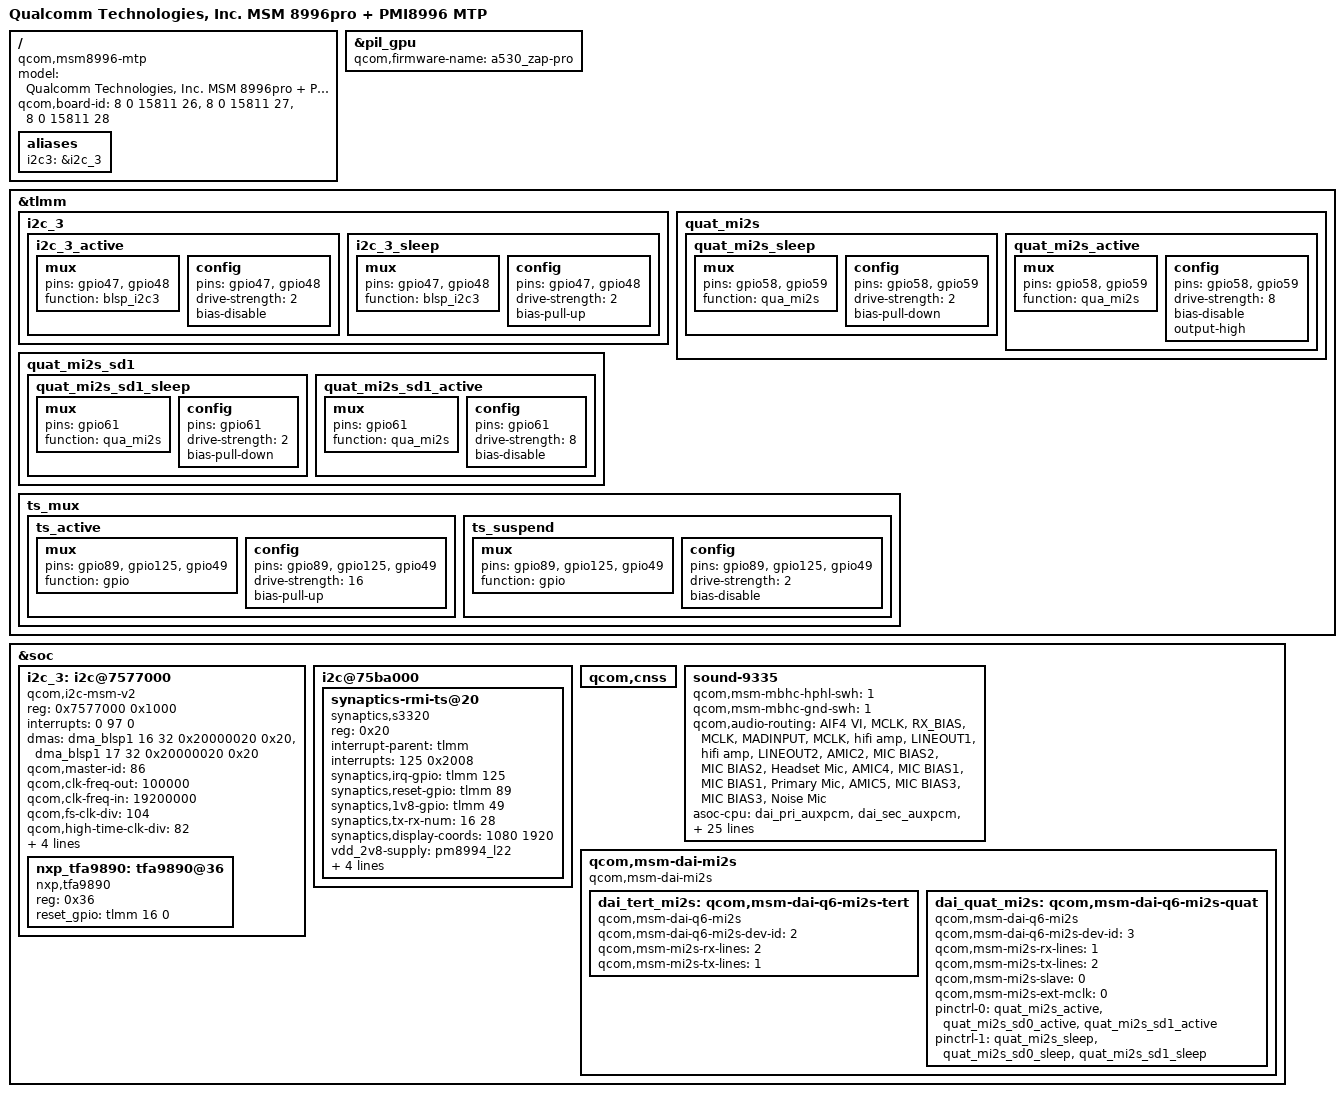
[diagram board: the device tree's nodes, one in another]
/*
 * Copyright (C) 2018, Comma.ai, Inc.
 *
 * This program is free software; you can redistribute it and/or modify
 * it under the terms of the GNU General Public License version 2 and
 * only version 2 as published by the Free Software Foundation.
 *
 * This program is distributed in the hope that it will be useful,
 * but WITHOUT ANY WARRANTY; without even the implied warranty of
 * MERCHANTABILITY or FITNESS FOR A PARTICULAR PURPOSE.  See the
 * GNU General Public License for more details.
 */

/dts-v1/;

#include "msm8996pro.dtsi"
#include "msm-pmi8996.dtsi"
#include "msm8996-mtp.dtsi"
#include "dsi-panel-samsung_s6e3fa3_1080p_cmd.dtsi"
#include "dsi-panel-samsung_s6e3fa5_1080p_cmd.dtsi"
#include "dsi-panel-samsung_s6e3fa5r9s_1080p_cmd.dtsi"

/ {
	model = "Qualcomm Technologies, Inc. MSM 8996pro + PMI8996 MTP";
	compatible = "qcom,msm8996-mtp", "qcom,msm8996", "qcom,mtp";
	qcom,board-id = <8 0 15811 26>, <8 0 15811 27>, <8 0 15811 28>;

	aliases {
		i2c3 = &i2c_3;
	};
};

&pil_gpu {
	qcom,firmware-name = "a530_zap-pro";
};

&tlmm {
	i2c_3 {
		i2c_3_active: i2c_3_active {
			mux {
				pins = "gpio47", "gpio48";
				function = "blsp_i2c3";
			};

			config {
				pins = "gpio47", "gpio48";
				drive-strength = <2>;
				bias-disable;
			};
		};

		i2c_3_sleep: i2c_3_sleep {
			mux {
				pins = "gpio47", "gpio48";
				function = "blsp_i2c3";
			};

			config {
				pins = "gpio47", "gpio48";
				drive-strength = <2>;
				bias-pull-up;
			};
		};
	};

	quat_mi2s {
		quat_mi2s_sleep: quat_mi2s_sleep {
			mux {
				pins = "gpio58", "gpio59";
				function = "qua_mi2s";
			};

			config {
				pins = "gpio58", "gpio59";
				drive-strength = <2>;
				bias-pull-down;
			};
		};

		quat_mi2s_active: quat_mi2s_active {
			mux {
				pins = "gpio58", "gpio59";
				function = "qua_mi2s";
			};

			config {
				pins = "gpio58", "gpio59";
				drive-strength = <8>;
				bias-disable;
				output-high;
			};
		};
	};

	quat_mi2s_sd1 {
		quat_mi2s_sd1_sleep: quat_mi2s_sd1_sleep {
			mux {
				pins = "gpio61";
				function = "qua_mi2s";
			};

			config {
				pins = "gpio61";
				drive-strength = <2>;
				bias-pull-down;
			};
		};

		quat_mi2s_sd1_active: quat_mi2s_sd1_active {
			mux {
				pins = "gpio61";
				function = "qua_mi2s";
			};

			config {
				pins = "gpio61";
				drive-strength = <8>;
				bias-disable;
			};
		};
	};

	ts_mux {
		ts_active: ts_active {
			mux {
				pins = "gpio89", "gpio125","gpio49";
				function = "gpio";
			};

			config {
				pins = "gpio89", "gpio125","gpio49";
				drive-strength = <16>;
				bias-pull-up;
			};
		};

		ts_suspend: ts_suspend {
			mux {
				pins = "gpio89", "gpio125","gpio49";
				function = "gpio";
			};

			config {
				pins = "gpio89", "gpio125","gpio49";
				drive-strength = <2>;
				bias-disable;
			};
		};
	};
};

&soc {
	i2c_3: i2c@7577000 {
		compatible = "qcom,i2c-msm-v2";
		#address-cells = <1>;
		#size-cells = <0>;
		reg-names = "qup_phys_addr";
		reg = <0x7577000 0x1000>;
		interrupt-names = "qup_irq";
		interrupts = <0 97 0>;
		dmas = <&dma_blsp1 16 32 0x20000020 0x20>,
		<&dma_blsp1 17 32 0x20000020 0x20>;
		dma-names = "tx", "rx";
		qcom,master-id = <86>;
		qcom,clk-freq-out = <100000>;
		qcom,clk-freq-in = <19200000>;
		qcom,fs-clk-div =<104>;
		qcom,high-time-clk-div=<82>;
		clock-names = "iface_clk", "core_clk";
		clocks = <&clock_gcc clk_gcc_blsp1_ahb_clk>,
		<&clock_gcc clk_gcc_blsp1_qup3_i2c_apps_clk>;
		pinctrl-names = "i2c_active", "i2c_sleep";
		pinctrl-0 = <&i2c_3_active>;
		pinctrl-1 = <&i2c_3_sleep>;

		nxp_tfa9890: tfa9890@36 {
			compatible = "nxp,tfa9890";
			reg = <0x36>;
			reset_gpio= <&tlmm 16 0>;
			status = "ok";
		};
	};

	i2c@75ba000 {
		/delete-node/ synaptics@20;

		synaptics-rmi-ts@20 {
			compatible = "synaptics,s3320";
			reg = <0x20>;
			interrupt-parent = <&tlmm>;
			interrupts = <125 0x2008>;
			synaptics,irq-gpio = <&tlmm 125 0x2008>;
			synaptics,reset-gpio = <&tlmm 89 0x00>;
			synaptics,1v8-gpio = <&tlmm 49 0x00>;
			synaptics,tx-rx-num = <16 28>;
			synaptics,display-coords = <1080 1920>;
			vdd_2v8-supply = <&pm8994_l22>;
			vcc_i2c_1v8-supply = <&pm8994_s4>;
			oem,support_hw_poweroff;
			pinctrl-names = "pmx_ts_active", "pmx_ts_suspend";
			pinctrl-0 = <&ts_active>;
			pinctrl-1 = <&ts_suspend>;
		};
	};

	qcom,cnss {
		/delete-property/ qcom,wlan-ramdump-dynamic;
	};

	sound-9335 {
		/delete-property/ qcom,hph-en1-gpio;
		/delete-property/ qcom,hph-en0-gpio;
		/delete-property/ qcom,wsa-devs;
		/delete-property/ qcom,wsa-aux-dev-prefix;

		qcom,msm-mbhc-hphl-swh = <1>;
		qcom,msm-mbhc-gnd-swh = <1>;
		qcom,audio-routing =
			"AIF4 VI", "MCLK",
			"RX_BIAS", "MCLK",
			"MADINPUT", "MCLK",
			"hifi amp", "LINEOUT1",
			"hifi amp", "LINEOUT2",
			"AMIC2", "MIC BIAS2",
			"MIC BIAS2", "Headset Mic",
			"AMIC4", "MIC BIAS1",
			"MIC BIAS1", "Primary Mic",
			"AMIC5", "MIC BIAS3",
			"MIC BIAS3", "Noise Mic";

		asoc-cpu = <&dai_pri_auxpcm>, <&dai_sec_auxpcm>, <&dai_hdmi>,
				<&dai_tert_mi2s>, <&dai_quat_mi2s>,
				<&sb_0_rx>, <&sb_0_tx>, <&sb_1_rx>, <&sb_1_tx>,
				<&sb_2_rx>, <&sb_2_tx>, <&sb_3_rx>, <&sb_3_tx>,
				<&sb_4_rx>, <&sb_4_tx>, <&sb_5_tx>, <&afe_pcm_rx>,
				<&afe_pcm_tx>, <&afe_proxy_rx>, <&afe_proxy_tx>,
				<&incall_record_rx>, <&incall_record_tx>,
				<&incall_music_rx>, <&incall_music2_rx>,
				<&sb_5_rx>, <&sb_6_rx>;
		asoc-cpu-names = "msm-dai-q6-auxpcm.1", "msm-dai-q6-auxpcm.2",
				"msm-dai-q6-hdmi.8",
				"msm-dai-q6-mi2s.2", "msm-dai-q6-mi2s.3",
				"msm-dai-q6-dev.16384", "msm-dai-q6-dev.16385",
				"msm-dai-q6-dev.16386", "msm-dai-q6-dev.16387",
				"msm-dai-q6-dev.16388", "msm-dai-q6-dev.16389",
				"msm-dai-q6-dev.16390", "msm-dai-q6-dev.16391",
				"msm-dai-q6-dev.16392", "msm-dai-q6-dev.16393",
				"msm-dai-q6-dev.16395", "msm-dai-q6-dev.224",
				"msm-dai-q6-dev.225", "msm-dai-q6-dev.241",
				"msm-dai-q6-dev.240", "msm-dai-q6-dev.32771",
				"msm-dai-q6-dev.32772", "msm-dai-q6-dev.32773",
				"msm-dai-q6-dev.32770", "msm-dai-q6-dev.16394",
				"msm-dai-q6-dev.16396";
		asoc-codec = <&stub_codec>, <&nxp_tfa9890>;
		asoc-codec-names = "msm-stub-codec.1", "tfa98xx.3-0036";
	};

	qcom,msm-dai-mi2s {
		compatible = "qcom,msm-dai-mi2s";
		dai_tert_mi2s: qcom,msm-dai-q6-mi2s-tert {
			compatible = "qcom,msm-dai-q6-mi2s";
			qcom,msm-dai-q6-mi2s-dev-id = <2>;
			qcom,msm-mi2s-rx-lines = <2>;
			qcom,msm-mi2s-tx-lines = <1>;
			pinctrl-names = "default", "sleep";
		};
	};

	qcom,msm-dai-mi2s {
		compatible = "qcom,msm-dai-mi2s";
		dai_quat_mi2s: qcom,msm-dai-q6-mi2s-quat {
			compatible = "qcom,msm-dai-q6-mi2s";
			qcom,msm-dai-q6-mi2s-dev-id = <3>;
			qcom,msm-mi2s-rx-lines = <1>;
			qcom,msm-mi2s-tx-lines = <2>;
			qcom,msm-mi2s-slave = <0>;
			qcom,msm-mi2s-ext-mclk = <0>;
			pinctrl-names = "default", "sleep";
			pinctrl-0 = <&quat_mi2s_active &quat_mi2s_sd0_active &quat_mi2s_sd1_active>;
			pinctrl-1 = <&quat_mi2s_sleep &quat_mi2s_sd0_sleep &quat_mi2s_sd1_sleep>;
		};
	};
};
